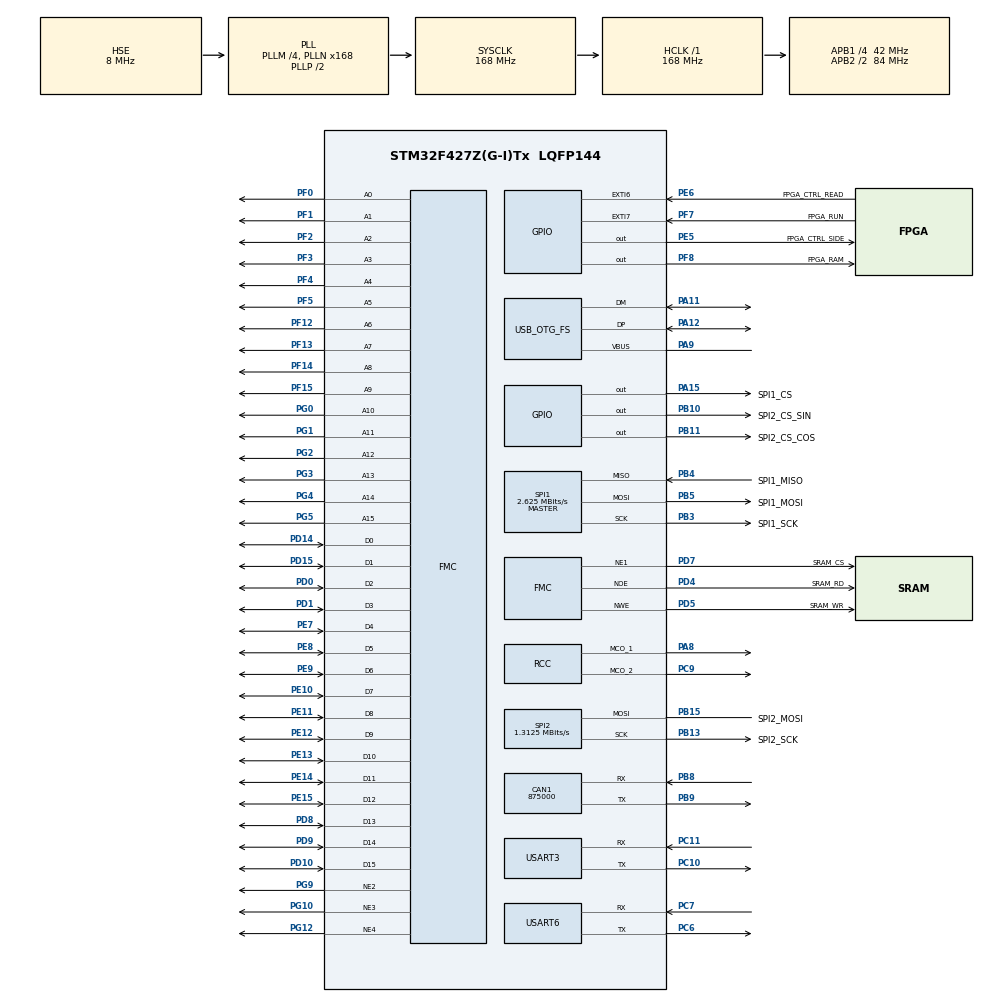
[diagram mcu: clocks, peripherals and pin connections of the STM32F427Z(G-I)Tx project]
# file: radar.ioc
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CAN1.CalculateBaudRate=875000
CAN1.CalculateTimeBit=1142
CAN1.CalculateTimeQuantum=380.95238095238096
FMC.AddressSetupTime1=2
FMC.AddressSetupTime2=2
FMC.AddressSetupTime3=2
FMC.AddressSetupTime4=2
FMC.BusTurnAroundDuration1=0
FMC.BusTurnAroundDuration2=0
FMC.BusTurnAroundDuration3=0
FMC.BusTurnAroundDuration4=0
FMC.DataSetupTime1=8
FMC.DataSetupTime2=8
FMC.DataSetupTime3=8
FMC.DataSetupTime4=8
FMC.ExtendedMode1=FMC_EXTENDED_MODE_DISABLE
FMC.ExtendedMode4=FMC_EXTENDED_MODE_DISABLE
FMC.WriteOperation1=FMC_WRITE_OPERATION_ENABLE
FMC.WriteOperation2=FMC_WRITE_OPERATION_ENABLE
FMC.WriteOperation3=FMC_WRITE_OPERATION_ENABLE
FMC.WriteOperation4=FMC_WRITE_OPERATION_ENABLE
Mcu.Family=STM32F4
Mcu.Name=STM32F427Z(G-I)Tx
Mcu.Package=LQFP144
NVIC.OTG_FS_IRQn=true\:0\:0\:false\:false\:true\:true\:true\:true
NVIC.PriorityGroup=NVIC_PRIORITYGROUP_4
NVIC.SPI1_IRQn=true\:0\:0\:false\:false\:true\:true\:true\:true
NVIC.SPI2_IRQn=true\:0\:0\:false\:false\:true\:true\:true\:true
NVIC.TIM3_IRQn=true\:0\:0\:false\:false\:true\:true\:true\:true
NVIC.TIM6_DAC_IRQn=true\:0\:0\:false\:false\:true\:true\:true\:true
NVIC.TIM8_TRG_COM_TIM14_IRQn=true\:15\:0\:false\:false\:true\:false\:true\:true
NVIC.TimeBase=TIM8_TRG_COM_TIM14_IRQn
NVIC.TimeBaseIP=TIM14
PA11.Mode=Device_Only
PA11.Signal=USB_OTG_FS_DM
PA12.Mode=Device_Only
PA12.Signal=USB_OTG_FS_DP
PA13.Mode=Serial_Wire
PA13.Signal=SYS_JTMS-SWDIO
PA14.Mode=Serial_Wire
PA14.Signal=SYS_JTCK-SWCLK
PA15.GPIO_Label=SPI1_CS
PA15.GPIO_Speed=GPIO_SPEED_FREQ_HIGH
PA15.Signal=GPIO_Output
PA8.Mode=Clock-out-1
PA8.Signal=RCC_MCO_1
PA9.Mode=Activate_VBUS
PA9.Signal=USB_OTG_FS_VBUS
PB10.GPIO_Label=SPI2_CS_SIN
PB10.GPIO_Speed=GPIO_SPEED_FREQ_HIGH
PB10.Signal=GPIO_Output
PB11.GPIO_Label=SPI2_CS_COS
PB11.GPIO_ModeDefaultOutputPP=GPIO_MODE_OUTPUT_PP
PB11.GPIO_PuPd=GPIO_PULLUP
PB11.GPIO_Speed=GPIO_SPEED_FREQ_HIGH
PB11.Signal=GPIO_Output
PB13.GPIO_Label=SPI2_SCK
PB13.Mode=Simplex_Bidirectional_Master
PB13.Signal=SPI2_SCK
PB15.GPIO_Label=SPI2_MOSI
PB15.Mode=Simplex_Bidirectional_Master
PB15.Signal=SPI2_MOSI
PB3.GPIO_Label=SPI1_SCK
PB3.Mode=Full_Duplex_Master
PB3.Signal=SPI1_SCK
PB4.GPIO_Label=SPI1_MISO
PB4.Mode=Full_Duplex_Master
PB4.Signal=SPI1_MISO
PB5.GPIO_Label=SPI1_MOSI
PB5.Mode=Full_Duplex_Master
PB5.Signal=SPI1_MOSI
PB8.Mode=CAN_Activate
PB8.Signal=CAN1_RX
PB9.Mode=CAN_Activate
PB9.Signal=CAN1_TX
PC10.Mode=Asynchronous
PC10.Signal=USART3_TX
PC11.Mode=Asynchronous
PC11.Signal=USART3_RX
PC6.Mode=Asynchronous
PC6.Signal=USART6_TX
PC7.Mode=Asynchronous
PC7.Signal=USART6_RX
PC9.Mode=Clock-out-2
PC9.Signal=RCC_MCO_2
PD0.Signal=FMC_D2_DA2
PD1.Signal=FMC_D3_DA3
PD10.Signal=FMC_D15_DA15
PD14.Signal=FMC_D0_DA0
PD15.Signal=FMC_D1_DA1
PD4.GPIO_Label=SRAM_RD
PD4.Signal=FMC_NOE
PD5.GPIO_Label=SRAM_WR
PD5.Signal=FMC_NWE
PD7.GPIO_Label=SRAM_CS
PD7.Mode=NorPsramChipSelect1_1
PD7.Signal=FMC_NE1
PD8.Signal=FMC_D13_DA13
PD9.Signal=FMC_D14_DA14
PE10.Signal=FMC_D7_DA7
PE11.Signal=FMC_D8_DA8
PE12.Signal=FMC_D9_DA9
PE13.Signal=FMC_D10_DA10
PE14.Signal=FMC_D11_DA11
PE15.Signal=FMC_D12_DA12
PE5.GPIO_Label=FPGA_CTRL_SIDE
PE5.GPIO_Speed=GPIO_SPEED_FREQ_HIGH
PE5.Signal=GPIO_Output
PE6.GPIO_Label=FPGA_CTRL_READ
PE6.Signal=GPXTI6
PE7.Signal=FMC_D4_DA4
PE8.Signal=FMC_D5_DA5
PE9.Signal=FMC_D6_DA6
PF0.Signal=FMC_A0
PF1.Signal=FMC_A1
PF12.Signal=FMC_A6
PF13.Signal=FMC_A7
PF14.Signal=FMC_A8
PF15.Signal=FMC_A9
PF2.Signal=FMC_A2
PF3.Signal=FMC_A3
PF4.Signal=FMC_A4
PF5.Signal=FMC_A5
PF7.GPIO_Label=FPGA_RUN
PF7.Signal=GPXTI7
PF8.GPIO_Label=FPGA_RAM
PF8.GPIO_Speed=GPIO_SPEED_FREQ_HIGH
PF8.Signal=GPIO_Output
PG0.Signal=FMC_A10
PG1.Signal=FMC_A11
PG10.Mode=NorPsramChipSelect3_3
PG10.Signal=FMC_NE3
PG12.Mode=NorPsramChipSelect4_4
PG12.Signal=FMC_NE4
PG2.Signal=FMC_A12
PG3.Signal=FMC_A13
PG4.Signal=FMC_A14_BA0
PG5.Signal=FMC_A15_BA1
PG9.Mode=NorPsramChipSelect2_2
PG9.Signal=FMC_NE2
PH0/OSC_IN.Mode=HSE-External-Oscillator
PH0/OSC_IN.Signal=RCC_OSC_IN
PH1/OSC_OUT.Mode=HSE-External-Oscillator
PH1/OSC_OUT.Signal=RCC_OSC_OUT
ProjectManager.HeapSize=0x200
ProjectManager.StackSize=0x400
ProjectManager.TargetToolchain=MDK-ARM V5.32
RCC.48MHZClocksFreq_Value=48000000
RCC.AHBFreq_Value=168000000
RCC.APB1CLKDivider=RCC_HCLK_DIV4
RCC.APB1Freq_Value=42000000
RCC.APB1TimFreq_Value=84000000
RCC.APB2CLKDivider=RCC_HCLK_DIV2
RCC.APB2Freq_Value=84000000
RCC.APB2TimFreq_Value=168000000
RCC.CortexFreq_Value=168000000
RCC.HCLKFreq_Value=168000000
RCC.HSE_VALUE=8000000
RCC.HSI_VALUE=16000000
RCC.LSE_VALUE=32768
RCC.PLLM=4
RCC.PLLN=168
RCC.PLLQ=7
RCC.RCC_MCODiv2=RCC_MCODIV_2
RCC.SYSCLKFreq_VALUE=168000000
RCC.SYSCLKSource=RCC_SYSCLKSOURCE_PLLCLK
RCC.VCOOutputFreq_Value=336000000
SH.FMC_A0.0=FMC_A0,16b-a1
SH.FMC_A0.1=FMC_A0,16b-a2
SH.FMC_A0.2=FMC_A0,16b-a3
SH.FMC_A0.3=FMC_A0,16b-a4
SH.FMC_A1.0=FMC_A1,16b-a1
SH.FMC_A1.1=FMC_A1,16b-a2
SH.FMC_A1.2=FMC_A1,16b-a3
SH.FMC_A1.3=FMC_A1,16b-a4
SH.FMC_A10.0=FMC_A10,16b-a1
SH.FMC_A10.1=FMC_A10,16b-a2
SH.FMC_A10.2=FMC_A10,16b-a3
SH.FMC_A10.3=FMC_A10,16b-a4
SH.FMC_A11.0=FMC_A11,16b-a1
SH.FMC_A11.1=FMC_A11,16b-a2
SH.FMC_A11.2=FMC_A11,16b-a3
SH.FMC_A11.3=FMC_A11,16b-a4
SH.FMC_A12.0=FMC_A12,16b-a1
SH.FMC_A12.1=FMC_A12,16b-a2
SH.FMC_A12.2=FMC_A12,16b-a3
SH.FMC_A12.3=FMC_A12,16b-a4
SH.FMC_A13.0=FMC_A13,16b-a1
SH.FMC_A13.1=FMC_A13,16b-a2
SH.FMC_A13.2=FMC_A13,16b-a3
SH.FMC_A13.3=FMC_A13,16b-a4
SH.FMC_A14_BA0.0=FMC_A14,16b-a1
SH.FMC_A14_BA0.1=FMC_A14,16b-a2
SH.FMC_A14_BA0.2=FMC_A14,16b-a3
SH.FMC_A14_BA0.3=FMC_A14,16b-a4
SH.FMC_A15_BA1.0=FMC_A15,16b-a1
SH.FMC_A15_BA1.1=FMC_A15,16b-a2
SH.FMC_A15_BA1.2=FMC_A15,16b-a3
SH.FMC_A15_BA1.3=FMC_A15,16b-a4
SH.FMC_A2.0=FMC_A2,16b-a1
SH.FMC_A2.1=FMC_A2,16b-a2
SH.FMC_A2.2=FMC_A2,16b-a3
SH.FMC_A2.3=FMC_A2,16b-a4
SH.FMC_A3.0=FMC_A3,16b-a1
SH.FMC_A3.1=FMC_A3,16b-a2
SH.FMC_A3.2=FMC_A3,16b-a3
SH.FMC_A3.3=FMC_A3,16b-a4
SH.FMC_A4.0=FMC_A4,16b-a1
SH.FMC_A4.1=FMC_A4,16b-a2
SH.FMC_A4.2=FMC_A4,16b-a3
SH.FMC_A4.3=FMC_A4,16b-a4
SH.FMC_A5.0=FMC_A5,16b-a1
SH.FMC_A5.1=FMC_A5,16b-a2
SH.FMC_A5.2=FMC_A5,16b-a3
SH.FMC_A5.3=FMC_A5,16b-a4
SH.FMC_A6.0=FMC_A6,16b-a1
SH.FMC_A6.1=FMC_A6,16b-a2
SH.FMC_A6.2=FMC_A6,16b-a3
SH.FMC_A6.3=FMC_A6,16b-a4
SH.FMC_A7.0=FMC_A7,16b-a1
SH.FMC_A7.1=FMC_A7,16b-a2
SH.FMC_A7.2=FMC_A7,16b-a3
SH.FMC_A7.3=FMC_A7,16b-a4
SH.FMC_A8.0=FMC_A8,16b-a1
SH.FMC_A8.1=FMC_A8,16b-a2
SH.FMC_A8.2=FMC_A8,16b-a3
SH.FMC_A8.3=FMC_A8,16b-a4
SH.FMC_A9.0=FMC_A9,16b-a1
SH.FMC_A9.1=FMC_A9,16b-a2
SH.FMC_A9.2=FMC_A9,16b-a3
SH.FMC_A9.3=FMC_A9,16b-a4
SH.FMC_D0_DA0.0=FMC_D0,16b-d1
SH.FMC_D0_DA0.1=FMC_D0,16b-d2
SH.FMC_D0_DA0.2=FMC_D0,16b-d3
SH.FMC_D0_DA0.3=FMC_D0,16b-d4
SH.FMC_D10_DA10.0=FMC_D10,16b-d1
SH.FMC_D10_DA10.1=FMC_D10,16b-d2
SH.FMC_D10_DA10.2=FMC_D10,16b-d3
SH.FMC_D10_DA10.3=FMC_D10,16b-d4
SH.FMC_D11_DA11.0=FMC_D11,16b-d1
SH.FMC_D11_DA11.1=FMC_D11,16b-d2
SH.FMC_D11_DA11.2=FMC_D11,16b-d3
SH.FMC_D11_DA11.3=FMC_D11,16b-d4
SH.FMC_D12_DA12.0=FMC_D12,16b-d1
SH.FMC_D12_DA12.1=FMC_D12,16b-d2
SH.FMC_D12_DA12.2=FMC_D12,16b-d3
SH.FMC_D12_DA12.3=FMC_D12,16b-d4
SH.FMC_D13_DA13.0=FMC_D13,16b-d1
SH.FMC_D13_DA13.1=FMC_D13,16b-d2
SH.FMC_D13_DA13.2=FMC_D13,16b-d3
SH.FMC_D13_DA13.3=FMC_D13,16b-d4
SH.FMC_D14_DA14.0=FMC_D14,16b-d1
SH.FMC_D14_DA14.1=FMC_D14,16b-d2
SH.FMC_D14_DA14.2=FMC_D14,16b-d3
SH.FMC_D14_DA14.3=FMC_D14,16b-d4
SH.FMC_D15_DA15.0=FMC_D15,16b-d1
SH.FMC_D15_DA15.1=FMC_D15,16b-d2
SH.FMC_D15_DA15.2=FMC_D15,16b-d3
SH.FMC_D15_DA15.3=FMC_D15,16b-d4
SH.FMC_D1_DA1.0=FMC_D1,16b-d1
SH.FMC_D1_DA1.1=FMC_D1,16b-d2
SH.FMC_D1_DA1.2=FMC_D1,16b-d3
SH.FMC_D1_DA1.3=FMC_D1,16b-d4
SH.FMC_D2_DA2.0=FMC_D2,16b-d1
SH.FMC_D2_DA2.1=FMC_D2,16b-d2
SH.FMC_D2_DA2.2=FMC_D2,16b-d3
SH.FMC_D2_DA2.3=FMC_D2,16b-d4
SH.FMC_D3_DA3.0=FMC_D3,16b-d1
SH.FMC_D3_DA3.1=FMC_D3,16b-d2
SH.FMC_D3_DA3.2=FMC_D3,16b-d3
SH.FMC_D3_DA3.3=FMC_D3,16b-d4
SH.FMC_D4_DA4.0=FMC_D4,16b-d1
SH.FMC_D4_DA4.1=FMC_D4,16b-d2
SH.FMC_D4_DA4.2=FMC_D4,16b-d3
SH.FMC_D4_DA4.3=FMC_D4,16b-d4
SH.FMC_D5_DA5.0=FMC_D5,16b-d1
SH.FMC_D5_DA5.1=FMC_D5,16b-d2
SH.FMC_D5_DA5.2=FMC_D5,16b-d3
SH.FMC_D5_DA5.3=FMC_D5,16b-d4
SH.FMC_D6_DA6.0=FMC_D6,16b-d1
SH.FMC_D6_DA6.1=FMC_D6,16b-d2
SH.FMC_D6_DA6.2=FMC_D6,16b-d3
SH.FMC_D6_DA6.3=FMC_D6,16b-d4
SH.FMC_D7_DA7.0=FMC_D7,16b-d1
SH.FMC_D7_DA7.1=FMC_D7,16b-d2
SH.FMC_D7_DA7.2=FMC_D7,16b-d3
SH.FMC_D7_DA7.3=FMC_D7,16b-d4
SH.FMC_D8_DA8.0=FMC_D8,16b-d1
SH.FMC_D8_DA8.1=FMC_D8,16b-d2
SH.FMC_D8_DA8.2=FMC_D8,16b-d3
SH.FMC_D8_DA8.3=FMC_D8,16b-d4
SH.FMC_D9_DA9.0=FMC_D9,16b-d1
SH.FMC_D9_DA9.1=FMC_D9,16b-d2
SH.FMC_D9_DA9.2=FMC_D9,16b-d3
SH.FMC_D9_DA9.3=FMC_D9,16b-d4
SH.FMC_NOE.0=FMC_NOE,Sram1
SH.FMC_NOE.1=FMC_NOE,Sram2
SH.FMC_NOE.2=FMC_NOE,Sram3
SH.FMC_NOE.3=FMC_NOE,Sram4
SH.FMC_NWE.0=FMC_NWE,Sram1
SH.FMC_NWE.1=FMC_NWE,Sram2
SH.FMC_NWE.2=FMC_NWE,Sram3
SH.FMC_NWE.3=FMC_NWE,Sram4
SPI1.BaudRatePrescaler=SPI_BAUDRATEPRESCALER_32
SPI1.CLKPhase=SPI_PHASE_2EDGE
SPI1.CLKPolarity=SPI_POLARITY_HIGH
SPI1.CalculateBaudRate=2.625 MBits/s
SPI1.Direction=SPI_DIRECTION_2LINES
SPI1.Mode=SPI_MODE_MASTER
SPI1.VirtualType=VM_MASTER
SPI2.BaudRatePrescaler=SPI_BAUDRATEPRESCALER_32
SPI2.CLKPhase=SPI_PHASE_2EDGE
SPI2.CLKPolarity=SPI_POLARITY_HIGH
SPI2.CalculateBaudRate=1.3125 MBits/s
SPI2.Direction=SPI_DIRECTION_1LINE
SPI2.Mode=SPI_MODE_MASTER
SPI2.VirtualType=VM_MASTER
TIM3.AutoReloadPreload=TIM_AUTORELOAD_PRELOAD_ENABLE
TIM3.Period=30000-1
TIM3.Prescaler=8400-1
TIM6.Period=30000-1
TIM6.Prescaler=8400-1
USART3.VirtualMode=VM_ASYNC
USART6.VirtualMode=VM_ASYNC
USB_OTG_FS.VirtualMode=Device_Only
VP_SYS_VS_tim14.Mode=TIM14
VP_TIM3_VS_ClockSourceINT.Mode=Internal
VP_TIM6_VS_ClockSourceINT.Mode=Enable_Timer
board=custom

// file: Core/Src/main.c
/* USER CODE BEGIN Header */
/**
  ******************************************************************************
  * @file           : main.c
  * @brief          : Main program body
  ******************************************************************************
  * @attention
  *
  * Copyright (c) 2025 STMicroelectronics.
  * All rights reserved.
  *
  * This software is licensed under terms that can be found in the LICENSE file
  * in the root directory of this software component.
  * If no LICENSE file comes with this software, it is provided AS-IS.
  *
  ******************************************************************************
  */
/* USER CODE END Header */
#include "main.h"
#include "can.h"
#include "spi.h"
#include "tim.h"
#include "usart.h"
#include "usb_otg.h"
#include "gpio.h"
#include "fmc.h"

/* USER CODE BEGIN Includes */
#include "malloc.h"
#include "usbd_core.h"
#include "usbd_desc.h"
#include "usbd_cdc.h"
#include "usbd_cdc_interface.h"
/* USER CODE END Includes */

/* USER CODE BEGIN PV */
extern USBD_HandleTypeDef USBD_Device;  /* USB Device处理结构体 */
extern volatile uint8_t g_device_state; /* USB连接 情况 */
/* USER CODE END PV */

void SystemClock_Config(void);

int main(void)
{

  /* MCU Configuration--------------------------------------------------------*/

  /* Reset of all peripherals, Initializes the Flash interface and the Systick. */
  HAL_Init();

  /* Configure the system clock */
  SystemClock_Config();

  /* Initialize all configured peripherals */
  MX_GPIO_Init();
  MX_FMC_Init();
  MX_SPI1_Init();
  MX_SPI2_Init();
  MX_CAN1_Init();
  MX_USART3_UART_Init();
  MX_USART6_UART_Init();
  MX_USB_OTG_FS_PCD_Init();
  MX_TIM3_Init();
  MX_TIM6_Init();
  /* USER CODE BEGIN 2 */
    /* USB初始化 */
    USBD_Init(&USBD_Device, &VCP_Desc, 0);                    /* 初始化USB */
    USBD_RegisterClass(&USBD_Device, USBD_CDC_CLASS);         /* 添加类 */
    USBD_CDC_RegisterInterface(&USBD_Device, &USBD_CDC_fops); /* 为MSC类添加回调函数 */
    USBD_Start(&USBD_Device);                                 /* 开启USB */
  /* USER CODE END 2 */

  /* Infinite loop */
  while (1)
  {

  }
}

void SystemClock_Config(void)
{
  RCC_OscInitTypeDef RCC_OscInitStruct = {0};
  RCC_ClkInitTypeDef RCC_ClkInitStruct = {0};

  /** Configure the main internal regulator output voltage
  */
  __HAL_RCC_PWR_CLK_ENABLE();
  __HAL_PWR_VOLTAGESCALING_CONFIG(PWR_REGULATOR_VOLTAGE_SCALE1);

  /** Initializes the RCC Oscillators according to the specified parameters
  * in the RCC_OscInitTypeDef structure.
  */
  RCC_OscInitStruct.OscillatorType = RCC_OSCILLATORTYPE_HSI|RCC_OSCILLATORTYPE_HSE;
  RCC_OscInitStruct.HSEState = RCC_HSE_ON;
  RCC_OscInitStruct.HSIState = RCC_HSI_ON;
  RCC_OscInitStruct.HSICalibrationValue = RCC_HSICALIBRATION_DEFAULT;
  RCC_OscInitStruct.PLL.PLLState = RCC_PLL_ON;
  RCC_OscInitStruct.PLL.PLLSource = RCC_PLLSOURCE_HSE;
  RCC_OscInitStruct.PLL.PLLM = 4;
  RCC_OscInitStruct.PLL.PLLN = 168;
  RCC_OscInitStruct.PLL.PLLP = RCC_PLLP_DIV2;
  RCC_OscInitStruct.PLL.PLLQ = 7;
  if (HAL_RCC_OscConfig(&RCC_OscInitStruct) != HAL_OK)
  {
    Error_Handler();
  }

  /** Initializes the CPU, AHB and APB buses clocks
  */
  RCC_ClkInitStruct.ClockType = RCC_CLOCKTYPE_HCLK|RCC_CLOCKTYPE_SYSCLK
                              |RCC_CLOCKTYPE_PCLK1|RCC_CLOCKTYPE_PCLK2;
  RCC_ClkInitStruct.SYSCLKSource = RCC_SYSCLKSOURCE_PLLCLK;
  RCC_ClkInitStruct.AHBCLKDivider = RCC_SYSCLK_DIV1;
  RCC_ClkInitStruct.APB1CLKDivider = RCC_HCLK_DIV4;
  RCC_ClkInitStruct.APB2CLKDivider = RCC_HCLK_DIV2;

  if (HAL_RCC_ClockConfig(&RCC_ClkInitStruct, FLASH_LATENCY_5) != HAL_OK)
  {
    Error_Handler();
  }
  HAL_RCC_MCOConfig(RCC_MCO1, RCC_MCO1SOURCE_HSI, RCC_MCODIV_1);
  HAL_RCC_MCOConfig(RCC_MCO2, RCC_MCO2SOURCE_SYSCLK, RCC_MCODIV_2);
}

void HAL_TIM_PeriodElapsedCallback(TIM_HandleTypeDef *htim)
{
  if (htim->Instance == TIM14) {
    HAL_IncTick();
  }
}

void Error_Handler(void)
{
  __disable_irq();
  while (1)
  {
  }
}
